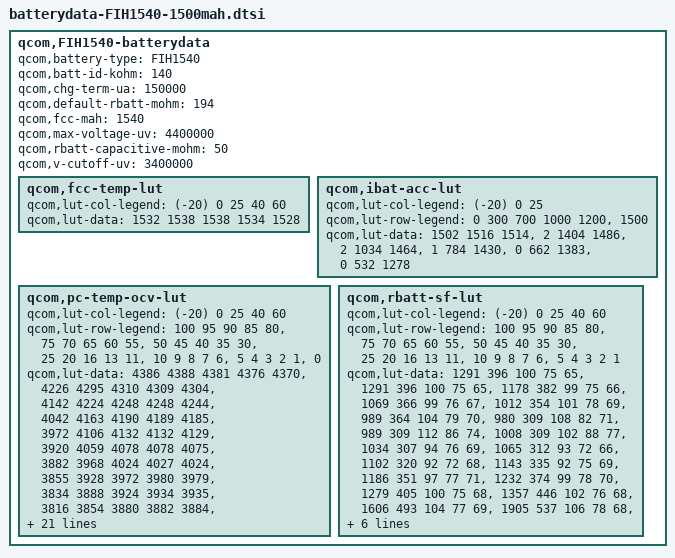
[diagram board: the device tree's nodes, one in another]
qcom,FIH1540-batterydata {
	qcom,battery-type = "FIH1540";
	qcom,batt-id-kohm = <140>;
	qcom,chg-term-ua = <150000>;
	qcom,default-rbatt-mohm = <194>;
	qcom,fcc-mah = <1540>;
	qcom,max-voltage-uv = <4400000>;
	qcom,rbatt-capacitive-mohm = <50>;
	qcom,v-cutoff-uv = <3400000>;

	qcom,fcc-temp-lut {
		qcom,lut-col-legend = <(-20) 0 25 40 60>;
		qcom,lut-data = <1532 1538 1538 1534 1528>;
	};

	qcom,ibat-acc-lut {
		qcom,lut-col-legend = <(-20) 0 25>;
		qcom,lut-row-legend = <0 300 700 1000 1200>,
					<1500>;
		qcom,lut-data = <1502 1516 1514>,
				<2 1404 1486>,
				<2 1034 1464>,
				<1 784 1430>,
				<0 662 1383>,
				<0 532 1278>;
	};

	qcom,pc-temp-ocv-lut {
		qcom,lut-col-legend = <(-20) 0 25 40 60>;
		qcom,lut-row-legend = <100 95 90 85 80>,
					<75 70 65 60 55>,
					<50 45 40 35 30>,
					<25 20 16 13 11>,
					<10 9 8 7 6>,
					<5 4 3 2 1>,
					<0>;
		qcom,lut-data = <4386 4388 4381 4376 4370>,
				<4226 4295 4310 4309 4304>,
				<4142 4224 4248 4248 4244>,
				<4042 4163 4190 4189 4185>,
				<3972 4106 4132 4132 4129>,
				<3920 4059 4078 4078 4075>,
				<3882 3968 4024 4027 4024>,
				<3855 3928 3972 3980 3979>,
				<3834 3888 3924 3934 3935>,
				<3816 3854 3880 3882 3884>,
				<3800 3826 3847 3848 3848>,
				<3784 3805 3821 3822 3822>,
				<3768 3790 3800 3802 3801>,
				<3752 3777 3783 3784 3784>,
				<3734 3764 3768 3767 3764>,
				<3714 3748 3756 3749 3738>,
				<3692 3730 3738 3730 3717>,
				<3670 3715 3718 3710 3696>,
				<3648 3704 3698 3690 3677>,
				<3632 3696 3688 3682 3670>,
				<3624 3691 3686 3680 3670>,
				<3614 3686 3685 3679 3668>,
				<3602 3679 3683 3678 3666>,
				<3586 3670 3680 3674 3662>,
				<3566 3657 3670 3664 3649>,
				<3544 3635 3645 3636 3616>,
				<3513 3598 3600 3590 3567>,
				<3470 3546 3537 3527 3504>,
				<3404 3468 3452 3443 3418>,
				<3281 3340 3325 3320 3294>,
				<3000 3000 3000 3000 3000>;
	};

	qcom,rbatt-sf-lut {
		qcom,lut-col-legend = <(-20) 0 25 40 60>;
		qcom,lut-row-legend = <100 95 90 85 80>,
					<75 70 65 60 55>,
					<50 45 40 35 30>,
					<25 20 16 13 11>,
					<10 9 8 7 6>,
					<5 4 3 2 1>;
		qcom,lut-data = <1291 396 100 75 65>,
				<1291 396 100 75 65>,
				<1178 382 99 75 66>,
				<1069 366 99 76 67>,
				<1012 354 101 78 69>,
				<989 364 104 79 70>,
				<980 309 108 82 71>,
				<989 309 112 86 74>,
				<1008 309 102 88 77>,
				<1034 307 94 76 69>,
				<1065 312 93 72 66>,
				<1102 320 92 72 68>,
				<1143 335 92 75 69>,
				<1186 351 97 77 71>,
				<1232 374 99 78 70>,
				<1279 405 100 75 68>,
				<1357 446 102 76 68>,
				<1606 493 104 77 69>,
				<1905 537 106 78 68>,
				<2144 571 108 77 68>,
				<2249 582 109 78 69>,
				<2401 595 112 80 70>,
				<2659 621 115 82 72>,
				<2988 652 121 84 72>,
				<3391 688 125 85 72>,
				<3935 725 126 83 71>,
				<4687 768 128 84 71>,
				<5791 830 137 86 72>,
				<7646 918 154 93 78>,
				<12162 1836 307 131 156>;
	};
};
